# ecd5_target_db register map
Vendor: Texas Instruments
Address unit: 16 bits
Registers are 32-bit, access per field, reset 0x0 unless marked. A register's access mark holds for its fields unless they carry their own. Offsets are as the file gives them; [hi:lo] are bit positions; {n}, {i} and the like mark numbered series; 'fields as' and 'values as' point back to an identical list; <NAME> marks a mode.

## DSS (part 5 of 5) — ipxact12_to_ccs_generated
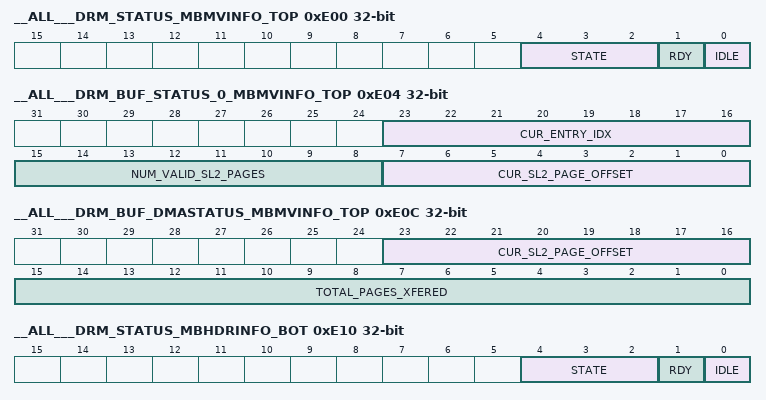
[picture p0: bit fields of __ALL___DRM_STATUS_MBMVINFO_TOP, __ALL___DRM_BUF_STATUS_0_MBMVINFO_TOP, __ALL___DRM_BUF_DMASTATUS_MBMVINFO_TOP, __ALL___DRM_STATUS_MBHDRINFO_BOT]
0xE00 __ALL___DRM_STATUS_MBMVINFO_TOP ro — Status of DRM channel controller forcurrent top MBMVInfo buffer
  [4:2] STATE — Indicates state of the channel control DRM FSM
  [1] RDY — Indicates availability of at least one valid page in SL2 for processing by the ECD core
  [0] IDLE — If "1", indicates that the DRM channel control FSM is IDLE. Used to check for completion of DMA after a terminate request.
0xE04 __ALL___DRM_BUF_STATUS_0_MBMVINFO_TOP ro — Buffer Status for current top MBMVInfo buffer Valid only in frame decoupled mode. Reflects the current internal and DMA status of the buffer
  [23:16] CUR_ENTRY_IDX — Unused
  [15:8] NUM_VALID_SL2_PAGES — Indicates the number of pages currently valid in SL2. This field indicates the number of pages in SL2 available for the ECD core to write into. This count is initialized to the total number of pages (ECD5_BE_BUFFER_CONTROL.DRM_BUF_CFG_[BUFFER_NAME].NUM_PAGES) on DRM initialization. The count is decremented every time ECD writes one page to SL2. The count is incremented whenever the DMA of one page from SL2 to DDR is completed.
  [7:0] CUR_SL2_PAGE_OFFSET — Indicates the SL2 page number where the next data will be written to by the ECD core (MBP); valid values are 0 to DRM_BUF_PARAMS_[BUFFER_NAME].NUM_PAGES - 1; reset on DMA initialization
0xE08 __ALL___DRM_BUF_STATUS_1_MBMVINFO_TOP ro — Buffer Status for current top MBMVInfo buffer Valid only in frame decoupled mode. Reflects the current internal and DMA status of the buffer
  [21:0] CUR_SL2_ADDR — Indicates the SL2 address of the page where the next data will be written to by the ECD core (MBP) ; reset on DMA initialization to SL2 base address of the buffer in SL2
0xE0C __ALL___DRM_BUF_DMASTATUS_MBMVINFO_TOP ro — Buffer DMA Status for current top MBMVInfo buffer Valid only in frame decoupled mode. Reflects the current DMA status of bin stream 3 buffer
  [23:16] CUR_SL2_PAGE_OFFSET — Indicates the SL2 page number from which the next page DMA will happen (read from) when enabling conditions for DMA are met (SL2 page is filled by ECD5 core); valid values are 0 to DRM_BUF_PARAMS_[BUFFER_NAME].NUM_PAGES - 1; reset on DMA initialization
  [15:0] TOTAL_PAGES_XFERED — Indicates the total number of pages for which DMA has completed; reset on DMA initialization
0xE10 __ALL___DRM_STATUS_MBHDRINFO_BOT ro — Status of DRM channel controller forcurrent bottom MBHdrInfo buffer
  fields as __ALL___DRM_STATUS_MBMVINFO_TOP
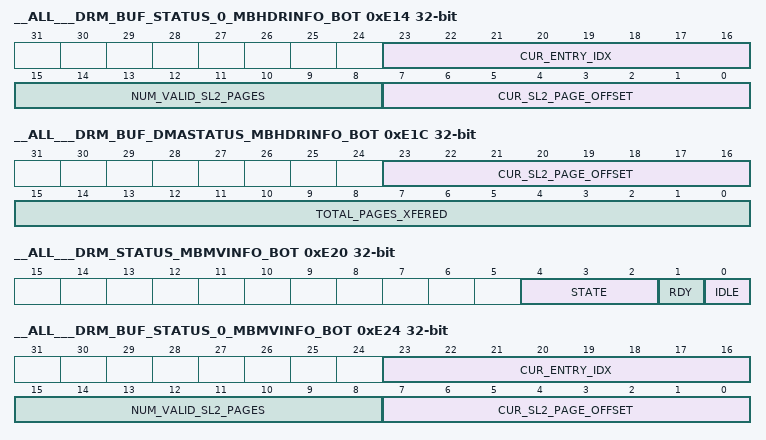
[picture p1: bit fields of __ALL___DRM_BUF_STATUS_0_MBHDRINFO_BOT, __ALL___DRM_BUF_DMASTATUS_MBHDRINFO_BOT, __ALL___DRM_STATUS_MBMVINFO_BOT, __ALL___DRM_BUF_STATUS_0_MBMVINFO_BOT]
0xE14 __ALL___DRM_BUF_STATUS_0_MBHDRINFO_BOT ro — Buffer Status for current bottom MBHdrInfo buffer Valid only in frame decoupled mode. Reflects the current internal and DMA status of the buffer
  [23:16] CUR_ENTRY_IDX — For debug only. Indicates the index of the entry that is currently being written or will be written next by the ECD5 core in the current page; reset on DMA initialization
  [15:8] NUM_VALID_SL2_PAGES — Indicates the number of pages currently valid in SL2. This field indicates the number of pages in SL2 available for the ECD core to write into. This count is initialized to the total number of pages (ECD5_BE_BUFFER_CONTROL.DRM_BUF_CFG_[BUFFER_NAME].NUM_PAGES) on DRM initialization. The count is decremented every time ECD writes one page to SL2. The count is incremented whenever the DMA of one page from SL2 to DDR is completed.
  [7:0] CUR_SL2_PAGE_OFFSET — Indicates the SL2 page number where the next data will be written to by the ECD core (MBP); valid values are 0 to DRM_BUF_PARAMS_[BUFFER_NAME].NUM_PAGES - 1; reset on DMA initialization
0xE18 __ALL___DRM_BUF_STATUS_1_MBHDRINFO_BOT ro — Buffer Status for current bottom MBHdrInfo buffer Valid only in frame decoupled mode. Reflects the current internal and DMA status of the buffer
  fields as __ALL___DRM_BUF_STATUS_1_MBMVINFO_TOP
0xE1C __ALL___DRM_BUF_DMASTATUS_MBHDRINFO_BOT ro — Buffer DMA Status for current bottom MBHdrInfo buffer Valid only in frame decoupled mode. Reflects the current DMA status of bin stream 3 buffer
  fields as __ALL___DRM_BUF_DMASTATUS_MBMVINFO_TOP
0xE20 __ALL___DRM_STATUS_MBMVINFO_BOT ro — Status of DRM channel controller forcurrent bottom MBMVInfo buffer
  fields as __ALL___DRM_STATUS_MBMVINFO_TOP
0xE24 __ALL___DRM_BUF_STATUS_0_MBMVINFO_BOT ro — Buffer Status for current bottom MBMVInfo buffer Valid only in frame decoupled mode. Reflects the current internal and DMA status of the buffer
  fields as __ALL___DRM_BUF_STATUS_0_MBMVINFO_TOP
0xE28 __ALL___DRM_BUF_STATUS_1_MBMVINFO_BOT ro — Buffer Status for current bottom MBMVInfo buffer Valid only in frame decoupled mode. Reflects the current internal and DMA status of the buffer
  fields as __ALL___DRM_BUF_STATUS_1_MBMVINFO_TOP
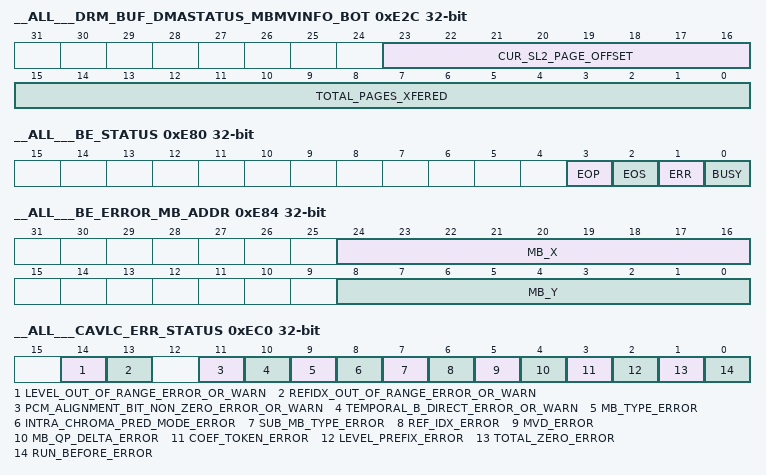
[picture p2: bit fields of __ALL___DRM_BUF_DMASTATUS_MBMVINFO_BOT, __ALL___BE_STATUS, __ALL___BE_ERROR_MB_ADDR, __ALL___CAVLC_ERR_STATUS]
0xE2C __ALL___DRM_BUF_DMASTATUS_MBMVINFO_BOT ro — Buffer DMA Status for current bottom MBMVInfo buffer Valid only in frame decoupled mode. Reflects the current DMA status of bin stream 3 buffer
  fields as __ALL___DRM_BUF_DMASTATUS_MBMVINFO_TOP
0xE80 __ALL___BE_STATUS ro — BE Status
  [3] EOP — Indicates End of Pipe (frame/sub-frame) was detected during decode of the last Macroblock. If set to 1, indicates that the last macroblock is at the end of the frame/sub-frame. On detecting EOP, ECD5 issues EOP interrupt (if enabled) and sets this flag. EOP flag is automatically cleared by ECD5 core if one of the following condition is true: - EN bit in SYSTEM_MMR.ECD5_BE_ENABLE register is set to 1 - hwa_init request is received
  [2] EOS — Indicates End of Slice was detected during decode of the last Macroblock. If set to 1, indicates that the last macroblock is at the end of the slice. When receiving EOS signal from codec engine, ECD5 issues EOS interrupt (if enabled) and sets this flag. EOS flag is automatically cleared if either one of the following condition is true: - EN bit in SYSTEM_MMR.ECD5_BE_UNIT_ENABLE register is set to 1. - EN bit in SYSTEM_MMR.ECD5_BE_ENABLE register is set to 1 - hwa_init request is received
  [1] ERR — Indicates Error was detected during decode of last Macroblock. If set to 1, indicates that the last macroblock had error. When receiving ERR signal from codec engine, ECD5 issues ERR interrupt (if enabled) and sets this flag. ERR flag is automatically cleared if either one of the following condition is true: - EN bit in SYSTEM_MMR.ECD5_BE_UNIT_ENABLE register is set to 1. - EN bit in SYSTEM_MMR.ECD5_BE_ENABLE register is set to 1. - start of new macroblock processing - hwa_init request is received
  [0] BUSY — Indicates whether the BE-MBP is busy 0 - Idle 1 - Busy
0xE84 __ALL___BE_ERROR_MB_ADDR ro — Error MB address This register provides the address of the MB in which error was detected by BE core or by CAVLC
  [24:16] MB_X — Specifies the X position of the error MB
  [8:0] MB_Y — Specifies the Y position of the error MB
0xEA0 __ALL___BE_CORE_STATIC_MB_COUNT rw — Static MB count
  [31:0] BE_CORE_STATIC_MB_COUNT — Count of H.241 static MBs (section 8.3.2.8 of H.241 standard)
0xEA4 __ALL___BE_CORE_ERR_STATUS — BE Error Status
  [0] TEMPORAL_B_DIRECT_MISSING_REF_ERROR rw — This bit is set if (frame_id, bottomFieldFlag) is not found in RefPicList.
0xEC0 __ALL___CAVLC_ERR_STATUS — CAVLC Error Status
  [14] LEVEL_OUT_OF_RANGE_ERROR_OR_WARN rw — This bit is set if level becomes out of range [-2^(7+bitDepth), 2^(7+bitDepth)-1] (due to error in level_suffix).
  [13] REFIDX_OUT_OF_RANGE_ERROR_OR_WARN rw — This bit is set if ref_idx_lx ( x == 0 or 1 ) out of the range [0,ECD5_BE_FUNC.CAVLC_REF_IDX_MAX_LX.VALUE] is detected
  [11] PCM_ALIGNMENT_BIT_NON_ZERO_ERROR_OR_WARN rw — This bit is set if pcm_alignment_zero_bit that is not "0" is detected
  [10] TEMPORAL_B_DIRECT_ERROR_OR_WARN rw — This bit is set if Temporal B Direct MB is detected.
  [9] MB_TYPE_ERROR rw — This bit is set if decoded mb_type_id is out of range. The range of mb_type_id is mb_type < 26 in I_SLICE, mb_type < 31 in P_SLICE, mb_type < 49 in B_SLICE
  [8] INTRA_CHROMA_PRED_MODE_ERROR rw — This bit is set if decoded intra_chroma_pred_mode is out of range. The range of intra_chroma_pred_mode is: intra_chroma_pred_mode < 4
  [7] SUB_MB_TYPE_ERROR rw — This bit is set if decoded sub_mb_type is out of range The range of sub_mb_type is: sub_mb_type_id < 4 in P_SLICE, sub_mb_type_id < 13 in B_SLICE.
  [6] REF_IDX_ERROR rw — This bit is set if decoded ref_idx_l0 or ref_idx_l1 is greater than 31.
  [5] MVD_ERROR rw — This bit is set if decoded MVD is out of range. The range of MVD is different between horizontal and vertical (Horizontal and vertical MVD have different out of range detectors) Valid Horizontal MVD range is [-16383,16383] in quarter-pel. Valid Vertical MVD range is [-4095,4095] in quarter-pel.
  [4] MB_QP_DELTA_ERROR rw — This bit is set if decoded mb_qp_delta is out of range. The range of mb_qp_delta is defined as follows: [-26,25] when bitDepth == 8, [-20,31] when bitDepth == 10, [-14,37] when bitDepth == 12.
  [3] COEF_TOKEN_ERROR rw — This bit is set if coef_token in bitstream is out of table or numcoef > max_coeff_num. * Caution: 8<=nC table is 6bit fixed length, but has error in the case 0b000010 and 0b000111. * Max_coeff_num is the number of maximum coefficients derived from block size, 15 or 16. * numcoef is the value derived from coef_token table.
  [2] LEVEL_PREFIX_ERROR rw — This bit is set if decoded level_prefix is out of range. The range of level_prefix is [0, (11+bitDepth)].
  [1] TOTAL_ZERO_ERROR rw — This bit is set if total zeros in bitstream is out of table or num_coeff + total_zeros > max_coeff_num.
  [0] RUN_BEFORE_ERROR rw — This bit is set if run_before in bitstream is out of table.
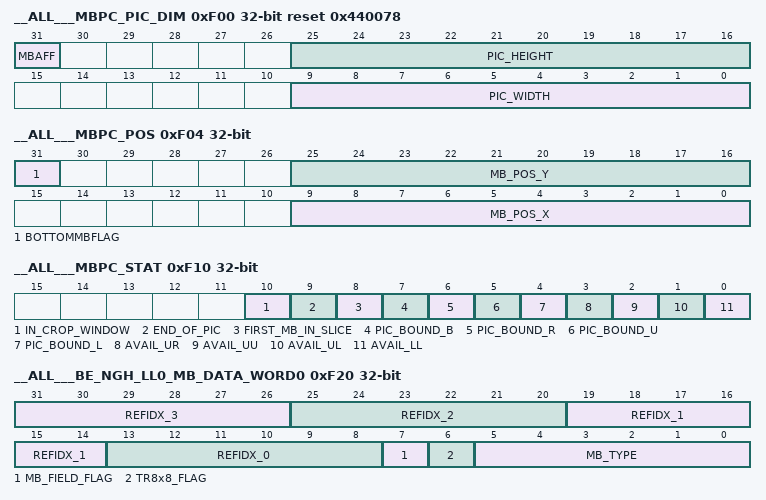
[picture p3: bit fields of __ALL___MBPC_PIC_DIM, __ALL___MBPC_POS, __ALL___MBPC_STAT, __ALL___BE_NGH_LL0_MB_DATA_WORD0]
0xF00 __ALL___MBPC_PIC_DIM rw reset 0x440078 — BE MBPC Picture Dimensions
  [31] MBAFF — If "1", current picture is MBAFF
  [25:16] PIC_HEIGHT — PictureHeight in MBs
  [9:0] PIC_WIDTH — Picture Width in MBs
0xF04 __ALL___MBPC_POS rw — BE MBPC Position
  [31] BOTTOMMBFLAG
  [25:16] MB_POS_Y — MB Position in X direction
  [9:0] MB_POS_X — MB Position in X direction
0xF08 __ALL___MBPC_PMC ro — BE MBPC MB count in picture
  [27:0] PIC_MB_COUNT — Picture level MB Count
0xF0C __ALL___MBPC_SMC ro — BE MBPC MB count in slice
  [27:0] SLICE_MB_COUNT — Slice level MB Count
0xF10 __ALL___MBPC_STAT — BE MBPC Status
  [10] IN_CROP_WINDOW rw — In crop window flag(for SVC)
  [9] END_OF_PIC rw — End of picture flag
  [8] FIRST_MB_IN_SLICE rw — First mb in slice flag
  [7] PIC_BOUND_B rw — Picture boundary bottom
  [6] PIC_BOUND_R rw — Picture boundary right
  [5] PIC_BOUND_U rw — Picture boundary top
  [4] PIC_BOUND_L rw — Picture boundary left
  [3] AVAIL_UR rw — UR neigbhor available
  [2] AVAIL_UU rw — UU neigbhor available
  [1] AVAIL_UL rw — UL neigbhor available
  [0] AVAIL_LL rw — LL neigbhor available
0xF20 __ALL___BE_NGH_LL0_MB_DATA_WORD0 rw — BE Left -Even Neighboring MB Data Word0
  [31:26] REFIDX_3 — L1 Reference Index for block # 13
  [25:20] REFIDX_2 — L1 Reference Index for block # 5
  [19:14] REFIDX_1 — L0 Reference Index for block # 13
  [13:8] REFIDX_0 — L0 Reference Index for block # 5
  [7] MB_FIELD_FLAG — MB Field Flag. Valid only for MBAFF
  [6] TR8x8_FLAG — Transform 8x8 Mode flag
  [5:0] MB_TYPE
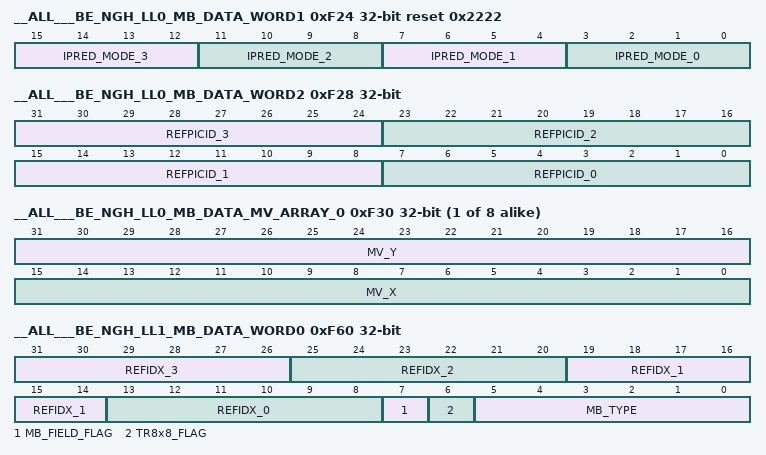
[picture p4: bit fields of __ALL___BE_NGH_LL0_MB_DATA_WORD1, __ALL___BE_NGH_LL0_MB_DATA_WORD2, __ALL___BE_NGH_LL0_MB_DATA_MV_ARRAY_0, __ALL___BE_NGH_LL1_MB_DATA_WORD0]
0xF24 __ALL___BE_NGH_LL0_MB_DATA_WORD1 reset 0x2222 — BE Left -Even Neighboring MB Data Word1
  [15:12] IPRED_MODE_3 rw — ipred_mode for block #15
  [11:8] IPRED_MODE_2 rw — ipred_mode for block #13
  [7:4] IPRED_MODE_1 rw — ipred_mode for block #7
  [3:0] IPRED_MODE_0 rw — ipred_mode for block #5
0xF28 __ALL___BE_NGH_LL0_MB_DATA_WORD2 rw — BE Left -Even Neighboring MB Data Word2
  [31:24] REFPICID_3 — L1 Reference PicId for block # 13
  [23:16] REFPICID_2 — L1 Reference PicId for block # 5
  [15:8] REFPICID_1 — L0 Reference PicId for block # 13
  [7:0] REFPICID_0 — L0 Reference PicId for block # 5
{0xF30+4i} __ALL___BE_NGH_LL0_MB_DATA_MV_ARRAY_{i} rw (i=0..7) — BE Left -Even Neighboring MB Data MV Register Array Indexed from 0 to 7
  [31:16] MV_Y — Ln Motion Vector, Y position for block M where index n M 0 0 10 1 0 11 2 0 14 3 0 15 4 1 10 5 1 11 6 1 14 7 1 15
  [15:0] MV_X — Ln Motion Vector, X position for block M where index n M 0 0 10 1 0 11 2 0 14 3 0 15 4 1 10 5 1 11 6 1 14 7 1 15
0xF60 __ALL___BE_NGH_LL1_MB_DATA_WORD0 rw — BE Left -Odd Neighboring MB Data Word0
  fields as __ALL___BE_NGH_LL0_MB_DATA_WORD0
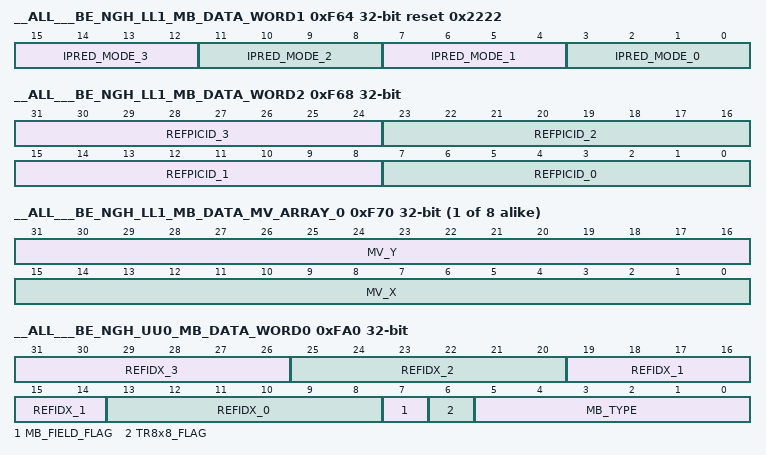
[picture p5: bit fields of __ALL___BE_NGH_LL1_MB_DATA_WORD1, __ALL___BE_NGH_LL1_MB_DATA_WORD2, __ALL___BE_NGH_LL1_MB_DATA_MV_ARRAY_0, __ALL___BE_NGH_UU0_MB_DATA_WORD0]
0xF64 __ALL___BE_NGH_LL1_MB_DATA_WORD1 reset 0x2222 — BE Left -Odd Neighboring MB Data Word1
  fields as __ALL___BE_NGH_LL0_MB_DATA_WORD1
0xF68 __ALL___BE_NGH_LL1_MB_DATA_WORD2 rw — BE Left -Odd Neighboring MB Data Word2
  fields as __ALL___BE_NGH_LL0_MB_DATA_WORD2
{0xF70+4i} __ALL___BE_NGH_LL1_MB_DATA_MV_ARRAY_{i} rw (i=0..7) — BE Left -Odd Neighboring MB Data MV Register Array Indexed from 0 to 7
  fields as __ALL___BE_NGH_LL0_MB_DATA_MV_ARRAY_0
0xFA0 __ALL___BE_NGH_UU0_MB_DATA_WORD0 rw — BE Upper -Even Neighboring MB Data Word0
  [31:26] REFIDX_3 — L1 Reference Index for block # 14
  [25:20] REFIDX_2 — L1 Reference Index for block # 10
  [19:14] REFIDX_1 — L0 Reference Index for block # 14
  [13:8] REFIDX_0 — L0 Reference Index for block # 10
  [7] MB_FIELD_FLAG — MB Field Flag. Valid only for MBAFF
  [6] TR8x8_FLAG — Transform 8x8 Mode flag
  [5:0] MB_TYPE
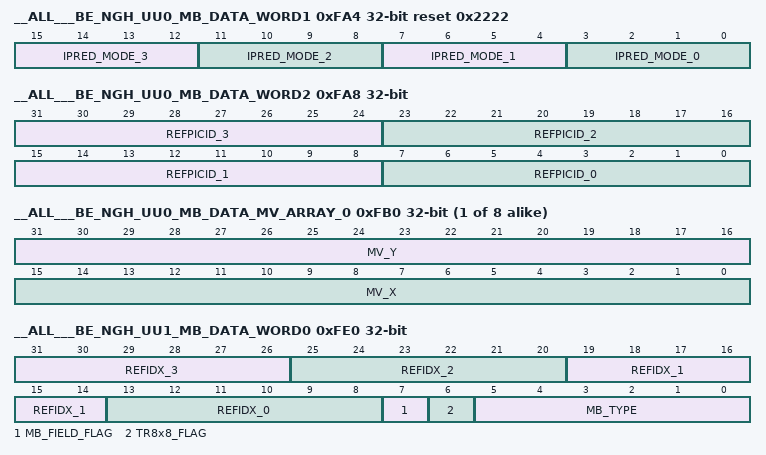
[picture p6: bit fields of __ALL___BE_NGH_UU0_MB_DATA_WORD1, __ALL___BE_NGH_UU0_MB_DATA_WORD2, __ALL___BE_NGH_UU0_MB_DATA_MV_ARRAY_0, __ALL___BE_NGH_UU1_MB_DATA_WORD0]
0xFA4 __ALL___BE_NGH_UU0_MB_DATA_WORD1 reset 0x2222 — BE Upper -Even Neighboring MB Data Word1
  [15:12] IPRED_MODE_3 rw — ipred_mode for block #15
  [11:8] IPRED_MODE_2 rw — ipred_mode for block #14
  [7:4] IPRED_MODE_1 rw — ipred_mode for block #11
  [3:0] IPRED_MODE_0 rw — ipred_mode for block #10
0xFA8 __ALL___BE_NGH_UU0_MB_DATA_WORD2 rw — BE Upper -Even Neighboring MB Data Word2
  [31:24] REFPICID_3 — L1 Reference PicId for block # 14
  [23:16] REFPICID_2 — L1 Reference PicId for block # 10
  [15:8] REFPICID_1 — L0 Reference PicId for block # 14
  [7:0] REFPICID_0 — L0 Reference PicId for block # 10
{0xFB0+4i} __ALL___BE_NGH_UU0_MB_DATA_MV_ARRAY_{i} rw (i=0..7) — BE Upper -Even Neighboring MB Data MV Register Array Indexed from 0 to 7
  fields as __ALL___BE_NGH_LL0_MB_DATA_MV_ARRAY_0
0xFE0 __ALL___BE_NGH_UU1_MB_DATA_WORD0 rw — BE Upper -Odd Neighboring MB Data MV0
  fields as __ALL___BE_NGH_UU0_MB_DATA_WORD0
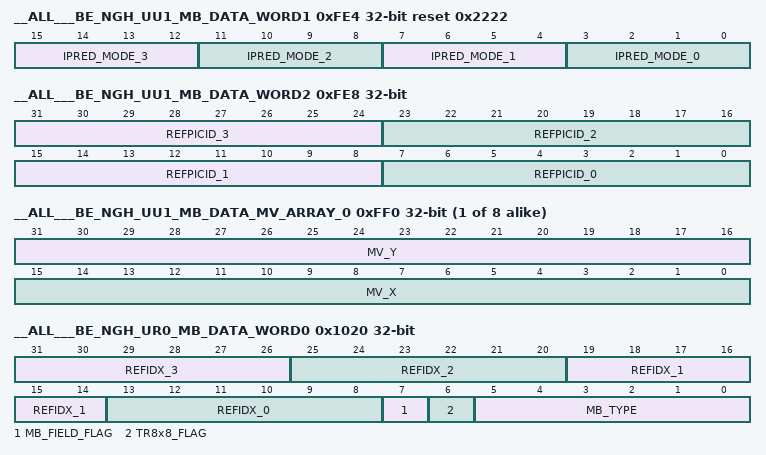
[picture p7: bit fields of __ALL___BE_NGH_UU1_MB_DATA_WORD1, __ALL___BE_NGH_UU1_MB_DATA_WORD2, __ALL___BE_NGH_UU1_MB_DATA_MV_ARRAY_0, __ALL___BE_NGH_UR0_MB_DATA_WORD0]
0xFE4 __ALL___BE_NGH_UU1_MB_DATA_WORD1 reset 0x2222 — BE Upper -Odd Neighboring MB Data Word1
  fields as __ALL___BE_NGH_UU0_MB_DATA_WORD1
0xFE8 __ALL___BE_NGH_UU1_MB_DATA_WORD2 rw — BE Upper -Odd Neighboring MB Data Word2
  fields as __ALL___BE_NGH_UU0_MB_DATA_WORD2
{0xFF0+4i} __ALL___BE_NGH_UU1_MB_DATA_MV_ARRAY_{i} rw (i=0..7) — BE Upper -Odd Neighboring MB Data MV Register Array Indexed from 0 to 7
  fields as __ALL___BE_NGH_LL0_MB_DATA_MV_ARRAY_0
0x1020 __ALL___BE_NGH_UR0_MB_DATA_WORD0 rw — BE Upper Right -Even Neighboring MB Data Word0
  fields as __ALL___BE_NGH_UU0_MB_DATA_WORD0
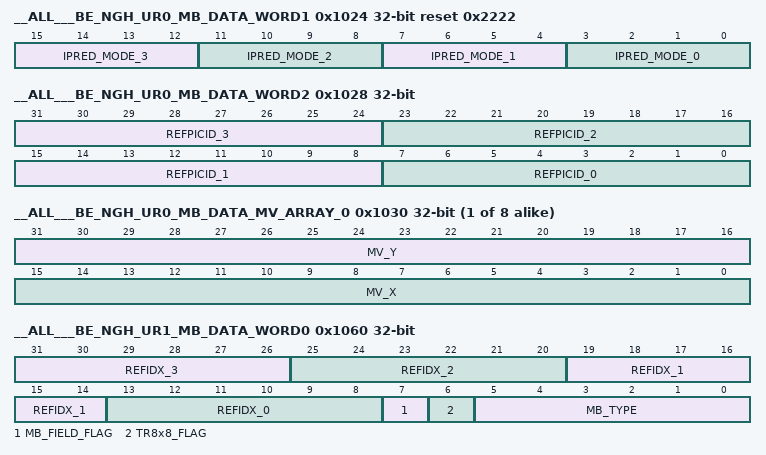
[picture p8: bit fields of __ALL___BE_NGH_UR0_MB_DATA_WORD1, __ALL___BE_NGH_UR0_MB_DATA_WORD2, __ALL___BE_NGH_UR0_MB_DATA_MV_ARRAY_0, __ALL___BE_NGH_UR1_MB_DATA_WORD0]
0x1024 __ALL___BE_NGH_UR0_MB_DATA_WORD1 reset 0x2222 — BE Upper Right -Even Neighboring MB Data Word1
  fields as __ALL___BE_NGH_UU0_MB_DATA_WORD1
0x1028 __ALL___BE_NGH_UR0_MB_DATA_WORD2 rw — BE Upper Right -Even Neighboring MB Data Word2
  fields as __ALL___BE_NGH_UU0_MB_DATA_WORD2
{0x1030+4i} __ALL___BE_NGH_UR0_MB_DATA_MV_ARRAY_{i} rw (i=0..7) — BE Upper Right -Even Neighboring MB Data MV Register Array Indexed from 0 to 7
  fields as __ALL___BE_NGH_LL0_MB_DATA_MV_ARRAY_0
0x1060 __ALL___BE_NGH_UR1_MB_DATA_WORD0 rw — BE Upper Right -Odd Neighboring MB Data Word0
  fields as __ALL___BE_NGH_UU0_MB_DATA_WORD0
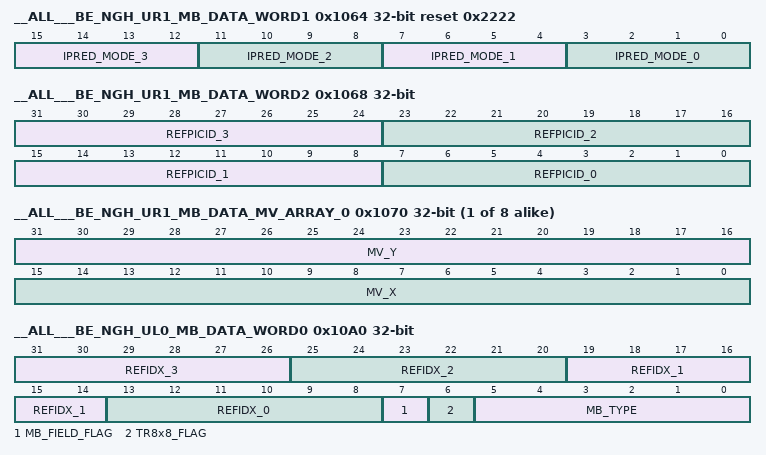
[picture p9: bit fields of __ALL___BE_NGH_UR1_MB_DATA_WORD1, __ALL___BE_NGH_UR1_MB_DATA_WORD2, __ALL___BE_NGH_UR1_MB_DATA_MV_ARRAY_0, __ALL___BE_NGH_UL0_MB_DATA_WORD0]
0x1064 __ALL___BE_NGH_UR1_MB_DATA_WORD1 reset 0x2222 — BE Upper Right -Odd Neighboring MB Data Word1
  fields as __ALL___BE_NGH_UU0_MB_DATA_WORD1
0x1068 __ALL___BE_NGH_UR1_MB_DATA_WORD2 rw — BE Upper Right -Odd Neighboring MB Data Word2
  fields as __ALL___BE_NGH_UU0_MB_DATA_WORD2
{0x1070+4i} __ALL___BE_NGH_UR1_MB_DATA_MV_ARRAY_{i} rw (i=0..7) — BE Upper Right -Odd Neighboring MB Data MV Register Array Indexed from 0 to 7
  fields as __ALL___BE_NGH_LL0_MB_DATA_MV_ARRAY_0
0x10A0 __ALL___BE_NGH_UL0_MB_DATA_WORD0 rw — BE Upper Left -Even Neighboring MB Data Word0
  fields as __ALL___BE_NGH_UU0_MB_DATA_WORD0
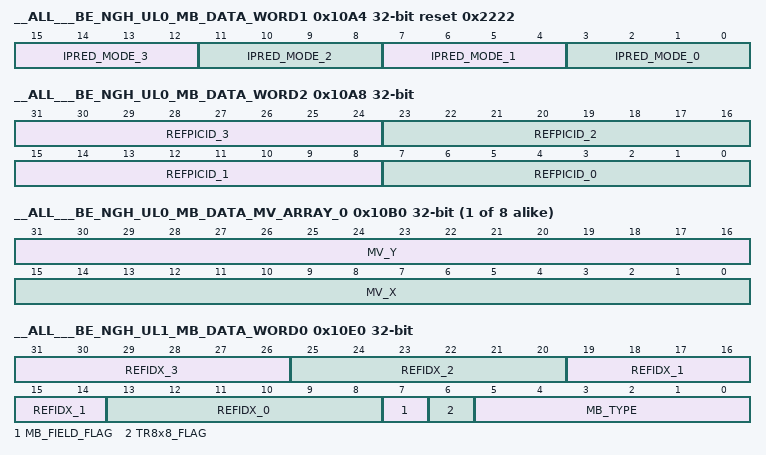
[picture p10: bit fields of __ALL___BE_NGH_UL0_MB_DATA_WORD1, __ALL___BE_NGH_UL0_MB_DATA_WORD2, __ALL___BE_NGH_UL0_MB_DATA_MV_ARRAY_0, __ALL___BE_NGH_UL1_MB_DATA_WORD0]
0x10A4 __ALL___BE_NGH_UL0_MB_DATA_WORD1 reset 0x2222 — BE Upper Left -Even Neighboring MB Data Word1
  fields as __ALL___BE_NGH_UU0_MB_DATA_WORD1
0x10A8 __ALL___BE_NGH_UL0_MB_DATA_WORD2 rw — BE Upper Left -Even Neighboring MB Data Word2
  fields as __ALL___BE_NGH_UU0_MB_DATA_WORD2
{0x10B0+4i} __ALL___BE_NGH_UL0_MB_DATA_MV_ARRAY_{i} rw (i=0..7) — BE Upper Left -Even Neighboring MB Data MV Register Array Indexed from 0 to 7
  fields as __ALL___BE_NGH_LL0_MB_DATA_MV_ARRAY_0
0x10E0 __ALL___BE_NGH_UL1_MB_DATA_WORD0 rw — BE Upper Left -Odd Neighboring MB Data Word0
  fields as __ALL___BE_NGH_UU0_MB_DATA_WORD0
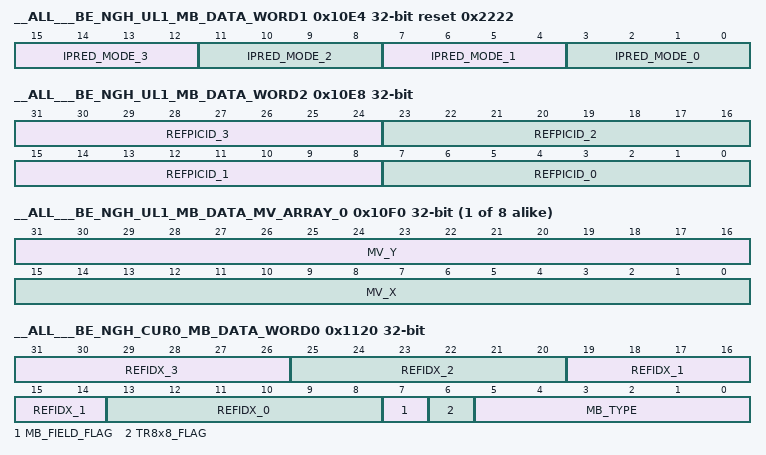
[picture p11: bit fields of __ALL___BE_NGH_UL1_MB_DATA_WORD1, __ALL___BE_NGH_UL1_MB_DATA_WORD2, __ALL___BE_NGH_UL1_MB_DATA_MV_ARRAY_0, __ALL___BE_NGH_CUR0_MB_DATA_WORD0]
0x10E4 __ALL___BE_NGH_UL1_MB_DATA_WORD1 reset 0x2222 — BE Upper Left -Odd Neighboring MB Data Word1
  fields as __ALL___BE_NGH_UU0_MB_DATA_WORD1
0x10E8 __ALL___BE_NGH_UL1_MB_DATA_WORD2 rw — BE Upper Left -Odd Neighboring MB Data Word2
  fields as __ALL___BE_NGH_UU0_MB_DATA_WORD2
{0x10F0+4i} __ALL___BE_NGH_UL1_MB_DATA_MV_ARRAY_{i} rw (i=0..7) — BE Upper Left -Odd Neighboring MB Data MV Register Array Indexed from 0 to 7
  fields as __ALL___BE_NGH_LL0_MB_DATA_MV_ARRAY_0
0x1120 __ALL___BE_NGH_CUR0_MB_DATA_WORD0 rw — BE Current -Even Neighboring MB Data Word0 (Needed Only for Bottom MB in MBAFF mode)
  fields as __ALL___BE_NGH_UU0_MB_DATA_WORD0
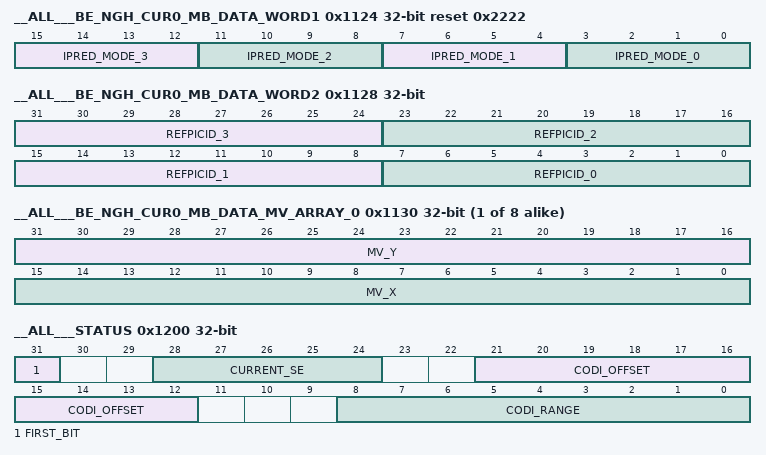
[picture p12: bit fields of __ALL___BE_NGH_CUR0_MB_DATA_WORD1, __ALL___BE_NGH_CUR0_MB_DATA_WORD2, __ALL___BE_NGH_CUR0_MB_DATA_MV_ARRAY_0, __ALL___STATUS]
0x1124 __ALL___BE_NGH_CUR0_MB_DATA_WORD1 reset 0x2222 — BE Current -Even Neighboring MB Data Word1
  fields as __ALL___BE_NGH_UU0_MB_DATA_WORD1
0x1128 __ALL___BE_NGH_CUR0_MB_DATA_WORD2 rw — BE Current -Even Neighboring MB Data Word2
  fields as __ALL___BE_NGH_UU0_MB_DATA_WORD2
{0x1130+4i} __ALL___BE_NGH_CUR0_MB_DATA_MV_ARRAY_{i} rw (i=0..7) — BE Current -Even Neighboring MB Data MV Register Array Indexed from 0 to 7
  fields as __ALL___BE_NGH_LL0_MB_DATA_MV_ARRAY_0
0x1200 __ALL___STATUS — Current status of CABAC Engine
  [31] FIRST_BIT rw — This bit equal to 1 indicates that the next bit put by CABAC is the first bit since the last CABAC initialization. This register is automatically set by CABAC encoder. This flag is ignored in decoding
  [28:24] CURRENT_SE ro — Current Syntax Element
  [21:12] CODI_OFFSET rw — Current Code Offset for CABAC encoding/decoding
  [8:0] CODI_RANGE rw — Current Code Range for CABAC encoding/decoding
0x1204 __ALL___BITS_OSTD rw — CABAC Outstanding bits
  [31:0] BITS_OSTD — Total number of outstanding bits in CABAC encoder. This register is not used in decoding.This register is maintained by ECD5.The value of this register is undefined if an error interrupt (INT_ERRx) is issued
0x1208 __ALL___BIN_COUNT rw — CABAC Bin count
  [31:0] COUNT — Total number of bins encoded/decoded. This register is reset to zero when H.264 core is invoked for a first macroblock in a slice or when CABAC decoder is invoked for an MB level execution. The value of this register is undefined if an error interrupt (int_err) is issued
{0x1300+4i} __ALL___NGH_UU0_PING_ARRAY_{i} rw (i=0..5) — Neighbouring A Top ping buffer
  [31:0] DATA
{0x1320+4i} __ALL___NGH_UU0_PONG_ARRAY_{i} rw (i=0..5) — Neighbouring A Top pong buffer
  [31:0] DATA
{0x1340+4i} __ALL___NGH_UU1_PING_ARRAY_{i} rw (i=0..5) — Neighbouring A Bottom ping buffer
  [31:0] DATA
{0x1360+4i} __ALL___NGH_UU1_PONG_ARRAY_{i} rw (i=0..5) — Neighbouring A Bottom pong buffer
  [31:0] DATA
{0x1380+4i} __ALL___NGH_LL0_PING_ARRAY_{i} rw (i=0..5) — Neighbouring B Top ping buffer
  [31:0] DATA
{0x13A0+4i} __ALL___NGH_LL0_PONG_ARRAY_{i} rw (i=0..5) — Neighbouring B Top pong buffer
  [31:0] DATA
{0x13C0+4i} __ALL___NGH_LL1_PING_ARRAY_{i} rw (i=0..5) — Neighbouring B Bottom ping buffer
  [31:0] DATA
{0x13E0+4i} __ALL___NGH_LL1_PONG_ARRAY_{i} rw (i=0..5) — Neighbouring B Bottom pong buffer
  [31:0] DATA
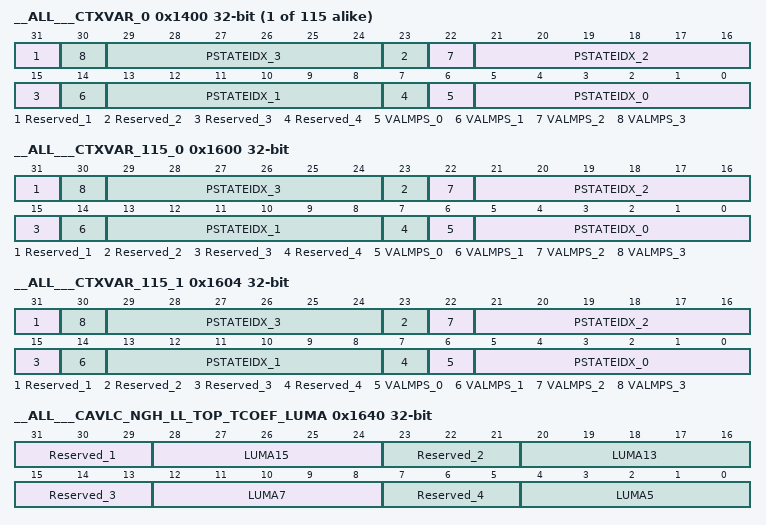
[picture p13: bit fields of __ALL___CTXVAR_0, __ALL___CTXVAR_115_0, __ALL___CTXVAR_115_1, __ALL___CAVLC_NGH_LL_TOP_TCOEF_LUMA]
{0x1400+4i} __ALL___CTXVAR_{i} (i=0..114) — CABAC Context Variable Register
  [39-8n] Reserved_{n} ro (n=1..4) — Fixed to 0. Writing this field is ignored. Reading this field returns always 0.
  [8n+6] VALMPS_{n} rw (n=0..3) — Most probable symbol for this CABAC context index
  [8n+5:8n] PSTATEIDX_{n} rw (n=0..3) — Probablility state index for this CABAC context index
0x1600 __ALL___CTXVAR_115_0 — CABAC Context Variable Register for contexts starting at 1024
  fields as __ALL___CTXVAR_0
0x1604 __ALL___CTXVAR_115_1 — CABAC Context Variable Register for contexts starting at 1024
  fields as __ALL___CTXVAR_0
0x1640 __ALL___CAVLC_NGH_LL_TOP_TCOEF_LUMA — CAVLC Neighbouring Total Coefficient Data for Luma blocks in Top MB of Left Neighbouring MB pair
  [39-8n:37-8n] Reserved_{n} ro (n=1..4) — Fixed to 0. Writing this field is ignored. Reading this field returns always 0.
  [28:24] LUMA15 rw — This register shows total_coef_luma15 of left_top data buffer. Writing this register causes the update of total_coef_luma15 field of left_top data buffer. Range of total_coef_luma is [0:16].
  [20:16] LUMA13 rw — This register shows total_coef_luma13 of left_top data buffer. Writing this register causes the update of total_coef_luma13 field of left_top data buffer. Range of total_coef_luma is [0:16].
  [12:8] LUMA7 rw — This register shows total_coef_luma7 of left_top data buffer. Writing this register causes the update of total_coef_luma7 field of left_top data buffer. Range of total_coef_luma is [0:16].
  [4:0] LUMA5 rw — This register shows total_coef_luma5 of left_top data buffer. Writing this register causes the update of total_coef_luma5 field of left_top data buffer. Range of total_coef_luma is [0:16].
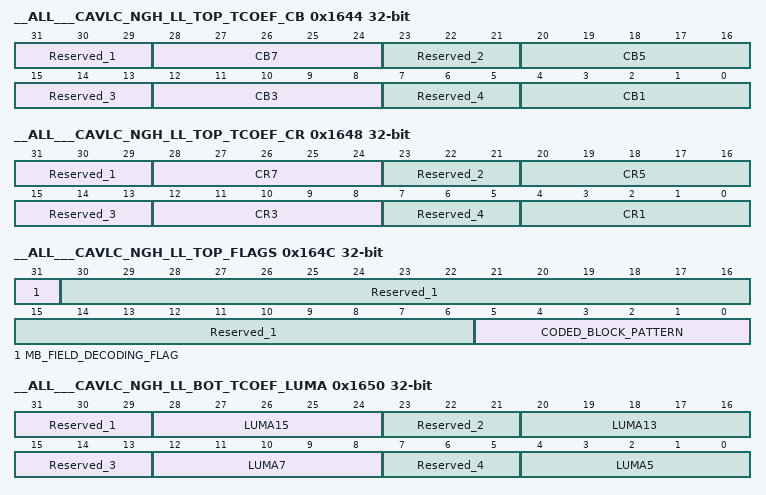
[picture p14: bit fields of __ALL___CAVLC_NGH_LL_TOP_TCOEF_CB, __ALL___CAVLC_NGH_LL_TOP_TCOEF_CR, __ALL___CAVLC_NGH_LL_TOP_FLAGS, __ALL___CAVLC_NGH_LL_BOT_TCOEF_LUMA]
0x1644 __ALL___CAVLC_NGH_LL_TOP_TCOEF_CB — CAVLC Neighbouring Total Coefficient Data for CB blocks in Top MB of Left Neighbouring MB pair
  [39-8n:37-8n] Reserved_{n} ro (n=1..4) — Fixed to 0. Writing this field is ignored. Reading this field returns always 0.
  [28:24] CB7 rw — This register shows total_coef_cb7 of left_top data buffer. Writing this register causes the update of total_coef_cb7 field of left_top data buffer. Range of total_coef_chroma is [0:16]. Only valid for 4:2:2 mode.
  [20:16] CB5 rw — This register shows total_coef_cb5 of left_top data buffer. Writing this register causes the update of total_coef_cb5 field of left_top data buffer. Range of total_coef_chroma is [0:16]. Only valid for 4:2:2 mode.
  [12:8] CB3 rw — This register shows total_coef_cb3 of left_top data buffer. Writing this register causes the update of total_coef_cb3 field of left_top data buffer. Range of total_coef_chroma is [0:16].
  [4:0] CB1 rw — This register shows total_coef_cb1 of left_top data buffer. Writing this register causes the update of total_coef_cb1 field of left_top data buffer. Range of total_coef_chroma is [0:16].
0x1648 __ALL___CAVLC_NGH_LL_TOP_TCOEF_CR — CAVLC Neighbouring Total Coefficient Data for CR blocks in Top MB of Left Neighbouring MB pair
  [39-8n:37-8n] Reserved_{n} ro (n=1..4) — Fixed to 0. Writing this field is ignored. Reading this field returns always 0.
  [28:24] CR7 rw — This register shows total_coef_cr7 of left_top data buffer. Writing this register causes the update of total_coef_cr7 field of left_top data buffer. Range of total_coef_chroma is [0:16]. Only valid for 4:2:2 mode.
  [20:16] CR5 rw — This register shows total_coef_cr5 of left_top data buffer. Writing this register causes the update of total_coef_cr5 field of left_top data buffer. Range of total_coef_chroma is [0:16]. Only valid for 4:2:2 mode.
  [12:8] CR3 rw — This register shows total_coef_cr3 of left_top data buffer. Writing this register causes the update of total_coef_cr3 field of left_top data buffer. Range of total_coef_chroma is [0:16].
  [4:0] CR1 rw — This register shows total_coef_cr1 of left_top data buffer. Writing this register causes the update of total_coef_cr1 field of left_top data buffer. Range of total_coef_chroma is [0:16].
0x164C __ALL___CAVLC_NGH_LL_TOP_FLAGS — CAVLC Neighbouring Flags in Top MB of Left Neighbouring MB pair
  [31] MB_FIELD_DECODING_FLAG rw — This register shows mb_field_decoding_flag of left_top data buffer. Writing this register causes the update of mb_field_decoding_flag field of left_top data buffer.
  [30:6] Reserved_1 ro — Fixed to 0. Writing this field is ignored. Reading this field returns always 0.
  [5:0] CODED_BLOCK_PATTERN rw — This register shows coded_block_pattern of left_top data buffer. Writing this register causes the update of coded_block_pattern field of left_top data buffer.
0x1650 __ALL___CAVLC_NGH_LL_BOT_TCOEF_LUMA — CAVLC Neighbouring Total Coefficient Data for Luma blocks in Bottom MB of Left Neighbouring MB pair
  [39-8n:37-8n] Reserved_{n} ro (n=1..4) — Fixed to 0. Writing this field is ignored. Reading this field returns always 0.
  [28:24] LUMA15 rw — This register shows total_coef_luma15 of left_bottom_data_array. Writing this register causes the update of total_coef_luma15 field of left_bottom_data_array. Range of total_coef_luma is [0:16].
  [20:16] LUMA13 rw — This register shows total_coef_luma13 of left_bottom_data_array. Writing this register causes the update of total_coef_luma13 field of left_bottom_data_array. Range of total_coef_luma is [0:16].
  [12:8] LUMA7 rw — This register shows total_coef_luma7 of left_bottom_data_array. Writing this register causes the update of total_coef_luma7 field of left_bottom_data_array. Range of total_coef_luma is [0:16].
  [4:0] LUMA5 rw — This register shows total_coef_luma5 of left_bottom_data_array. Writing this register causes the update of total_coef_luma5 field of left_bottom_data_array. Range of total_coef_luma is [0:16].
0x1654 __ALL___CAVLC_NGH_LL_BOT_TCOEF_CB — CAVLC Neighbouring Total Coefficient Data for CB blocks in Bottom MB of Left Neighbouring MB pair
  [39-8n:37-8n] Reserved_{n} ro (n=1..4) — Fixed to 0. Writing this field is ignored. Reading this field returns always 0.
  [28:24] CB7 rw — This register shows total_coef_cb7 of left_bottom data buffer. Writing this register causes the update of total_coef_cb7 field of left_bottom data buffer. Range of total_coef_chroma is [0:16]. Only valid for 4:2:2 mode.
  [20:16] CB5 rw — This register shows total_coef_cb5 of left_bottom data buffer. Writing this register causes the update of total_coef_cb5 field of left_bottom data buffer. Range of total_coef_chroma is [0:16]. Only valid for 4:2:2 mode.
  [12:8] CB3 rw — This register shows total_coef_cb3 of left_bottom data buffer. Writing this register causes the update of total_coef_cb3 field of left_bottom data buffer. Range of total_coef_chroma is [0:16].
  [4:0] CB1 rw — This register shows total_coef_cb1 of left_bottom data buffer. Writing this register causes the update of total_coef_cb1 field of left_bottom data buffer. Range of total_coef_chroma is [0:16].
0x1658 __ALL___CAVLC_NGH_LL_BOT_TCOEF_CR — CAVLC Neighbouring Total Coefficient Data for CR blocks in Bottom MB of Left Neighbouring MB pair
  [39-8n:37-8n] Reserved_{n} ro (n=1..4) — Fixed to 0. Writing this field is ignored. Reading this field returns always 0.
  [28:24] CR7 rw — This register shows total_coef_cr7 of left_bottom data buffer. Writing this register causes the update of total_coef_cr7 field of left_bottom data buffer. Range of total_coef_chroma is [0:16]. Only valid for 4:2:2 mode.
  [20:16] CR5 rw — This register shows total_coef_cr5 of left_bottom data buffer. Writing this register causes the update of total_coef_cr5 field of left_bottom data buffer. Range of total_coef_chroma is [0:16]. Only valid for 4:2:2 mode.
  [12:8] CR3 rw — This register shows total_coef_cr3 of left_bottom data buffer. Writing this register causes the update of total_coef_cr3 field of left_bottom data buffer. Range of total_coef_chroma is [0:16].
  [4:0] CR1 rw — This register shows total_coef_cr1 of left_bottom data buffer. Writing this register causes the update of total_coef_cr1 field of left_bottom data buffer. Range of total_coef_chroma is [0:16].
0x165C __ALL___CAVLC_NGH_LL_BOT_FLAGS — CAVLC Neighbouring Flags in Bottom MB of Left Neighbouring MB pair
  [31] MB_FIELD_DECODING_FLAG rw — This register shows mb_field_decoding_flag of left_bottom_data_array. Writing this register causes the update of mb_field_decoding_flag field of left_bottom_data_array.
  [30:6] Reserved_1 ro — Fixed to 0. Writing this field is ignored. Reading this field returns always 0.
  [5:0] CODED_BLOCK_PATTERN rw — This register shows coded_block_pattern of left_bottom_data_array. Writing this register causes the update of coded_block_pattern field of left_bottom_data_array.
0x1660 __ALL___CAVLC_NGH_PREV_TCOEF_LUMA0 — CAVLC Previous Data buffer Total Coefficient Data for Luma
  [39-8n:37-8n] Reserved_{n} ro (n=1..4) — Fixed to 0. Writing this field is ignored. Reading this field returns always 0.
  [28:24] LUMA15 rw — This register shows total_coef_luma15 of prev data buffer. Writing this register causes the update of total_coef_luma15 field of prev data buffer. Range of total_coef_luma is [0:16].
  [20:16] LUMA13 rw — This register shows total_coef_luma13 of prev data buffer. Writing this register causes the update of total_coef_luma13 field of prev data buffer. Range of total_coef_luma is [0:16].
  [12:8] LUMA7 rw — This register shows total_coef_luma7 of prev data buffer. Writing this register causes the update of total_coef_luma7 field of prev data buffer. Range of total_coef_luma is [0:16].
  [4:0] LUMA5 rw — This register shows total_coef_luma5 of prev data buffer. Writing this register causes the update of total_coef_luma5 field of prev data buffer. Range of total_coef_luma is [0:16].
0x1664 __ALL___CAVLC_NGH_PREV_TCOEF_LUMA1 — CAVLC Previous Data buffer Total Coefficient Data for Luma
  [31:21] Reserved_1 ro — Fixed to 0. Writing this field is ignored. Reading this field returns always 0.
  [20:16] LUMA14 rw — This register shows total_coef_luma14 of prev data buffer. Writing this register causes the update of total_coef_luma14 field of prev data buffer. Range of total_coef_luma is [0:16].
  [15:13] Reserved_2 ro — Fixed to 0. Writing this field is ignored. Reading this field returns always 0.
  [12:8] LUMA11 rw — This register shows total_coef_luma11 of prev data buffer. Writing this register causes the update of total_coef_luma11 field of prev data buffer. Range of total_coef_luma is [0:16].
  [7:5] Reserved_3 ro — Fixed to 0. Writing this field is ignored. Reading this field returns always 0.
  [4:0] LUMA10 rw — This register shows total_coef_luma10 of prev data buffer. Writing this register causes the update of total_coef_luma10 field of prev data buffer. Range of total_coef_luma is [0:16].
0x1668 __ALL___CAVLC_NGH_PREV_TCOEF_CB0 — CAVLC Previous Data buffer Total Coefficient Data for CB
  [39-8n:37-8n] Reserved_{n} ro (n=1..4) — Fixed to 0. Writing this field is ignored. Reading this field returns always 0.
  [28:24] CB7 rw — This register shows total_coef_cb7 of prev data buffer. Writing this register causes the update of total_coef_cb7 field of prev data buffer. Range of total_coef_chroma is [0:16]. Only valid for 4:2:2 mode.
  [20:16] CB5 rw — This register shows total_coef_cb5 of prev data buffer. Writing this register causes the update of total_coef_cb5 field of prev data buffer. Range of total_coef_chroma is [0:16]. Only valid for 4:2:2 mode.
  [12:8] CB3 rw — This register shows total_coef_cb3 of prev data buffer. Writing this register causes the update of total_coef_cb3 field of prev data buffer. Range of total_coef_chroma is [0:16].
  [4:0] CB1 rw — This register shows total_coef_cb1 of prev data buffer. Writing this register causes the update of total_coef_cb1 field of prev data buffer. Range of total_coef_chroma is [0:16].
0x166C __ALL___CAVLC_NGH_PREV_TCOEF_CB1 — CAVLC Previous Data buffer Total Coefficient Data for CB
  [31:13] Reserved_1 ro — Fixed to 0. Writing this field is ignored. Reading this field returns always 0.
  [12:8] CB6 rw — This register shows total_coef_cb11 of prev data buffer. Writing this register causes the update of total_coef_cb11 field of prev data buffer. Range of total_coef_cb is [0:16]. Only valid for 4:2:2 mode.
  [7:5] Reserved_2 ro — Fixed to 0. Writing this field is ignored. Reading this field returns always 0.
  [4:0] CB2 rw — This register shows total_coef_cb2 of prev data buffer. Writing this register causes the update of total_coef_cb2 field of prev data buffer. Range of total_coef_cb is [0:16]. Only valid for 4:2:0 mode
0x1670 __ALL___CAVLC_NGH_PREV_TCOEF_CR0 — CAVLC Previous Data buffer Total Coefficient Data for CR
  [39-8n:37-8n] Reserved_{n} ro (n=1..4) — Fixed to 0. Writing this field is ignored. Reading this field returns always 0.
  [28:24] CR7 rw — This register shows total_coef_cr7 of prev data buffer. Writing this register causes the update of total_coef_cr7 field of prev data buffer. Range of total_coef_chroma is [0:16]. Only valid for 4:2:2 mode.
  [20:16] CR5 rw — This register shows total_coef_cr5 of prev data buffer. Writing this register causes the update of total_coef_cr5 field of prev data buffer. Range of total_coef_chroma is [0:16]. Only valid for 4:2:2 mode.
  [12:8] CR3 rw — This register shows total_coef_cr3 of prev data buffer. Writing this register causes the update of total_coef_cr3 field of prev data buffer. Range of total_coef_chroma is [0:16].
  [4:0] CR1 rw — This register shows total_coef_cr1 of prev data buffer. Writing this register causes the update of total_coef_cr1 field of prev data buffer. Range of total_coef_chroma is [0:16].
0x1674 __ALL___CAVLC_NGH_PREV_TCOEF_CR1 — CAVLC Previous Data buffer Total Coefficient Data for CR
  [31:13] Reserved_1 ro — Fixed to 0. Writing this field is ignored. Reading this field returns always 0.
  [12:8] CR6 rw — This register shows total_coef_cr11 of prev data buffer. Writing this register causes the update of total_coef_cr11 field of prev data buffer. Range of total_coef_cr is [0:16]. Only valid for 4:2:2 mode.
  [7:5] Reserved_2 ro — Fixed to 0. Writing this field is ignored. Reading this field returns always 0.
  [4:0] CR2 rw — This register shows total_coef_cr10 of prev data buffer. Writing this register causes the update of total_coef_cr10 field of prev data buffer. Range of total_coef_cr is [0:16]. Only valid for 4:2:0 mode.
0x1678 __ALL___CAVLC_NGH_PREV_FLAGS — CAVLC Previous Data buffer Flags
  [31] MB_FIELD_DECODING_FLAG rw — This register shows mb_field_decoding_flag of prev data buffer. Writing this register causes the update of mb_field_decoding_flag field of prev data buffer.
  [30:6] Reserved_1 ro — Fixed to 0. Writing this field is ignored. Reading this field returns always 0.
  [5:0] CODED_BLOCK_PATTERN rw — This register shows coded_block_pattern of prev data buffer. Writing this register causes the update of coded_block_pattern field of prev data buffer.
0x167C __ALL___CAVLC_SKIP_RUN_CNT rw — CAVLC Skip Run Count
  [31:28] Reserved_1 — Fixed to 0. Writing this field is ignored. Reading this field returns always 0.
  [27:0] SKIP_RUN_CNT — Skip run counter. Writing this field is ignored during MB processing. After MB processing, this field shows the updated value of skip_run_cnt. Writing this field can be possible between MB processes. The written value is reflected at the beginning of MB processing.
0x1680 __ALL___CAVLC_SKIP_RUN_CNT_SHADOW rw — CAVLC Skip Run Count Shadow
  [31:28] Reserved_1 — Fixed to 0. Writing this field is ignored. Reading this field returns always 0.
  [27:0] SKIP_RUN_CNT — Skip run counter shadow register This register is copied with the value of CAVLC_SKIP_RUN_CNT.SKIP_RUN_CNT at the beginning of MB execution in CAVLC. Thus, when this register is read at the end of an MB execution ( MB N ), it contains that value of the skip run count that was valid at the end of the previous MB execution ( MB N-1 ). This register is to be used by S/W in H.241.
0x16C0 __ALL___DBG_CAP ro reset 0xE00200 — Debug Capability register. Used by debug software to determine which optional debug modules are present and how many instances of each module exist.
  [26] DBG_SWBP_SUP — Specifies whether HWA Core supports SWBP or not. 0 - Not Supported 1 - Supported
  [25] DBQ_RESET_SUP — Specifies whether HWA Core reset is supported or not which does not affect debug logic. 0 - Not Supported 1 - Supported
  [24] SYS_EXE_REQ — Whether HWA Core Execution status and control is supported. 0 - Not Supported 1 - Supported
  [23] TRIG_OUTPUT — 0 -Trigger Outputs are not supported 1 - Trigger Outputs are supported
  [22] TRIG_INPUT — 0 - Trigger Inputs are not supported 1 - Trigger Inputs are supported
  [21:20] TRIG_CHNS — Number of Trigger Channels Supported 0x0 - No channels supported 0x1- One channel supported 0x2 - Two channels supported Others - Reserved
  [19:16] NUM_CNTS — The number of counter modules that exist. The registers supporting the counter modules must be implemented consecutively in the memory map
  [15:12] NUM_WPS — The number of watchpoint modules that exist. The registers supporting the watchpoint modules must be implemented consecutively in the memory map
  [11:8] NUM_BPS — The number of breakpoint modules that exist. The registers supporting the breakpoint modules must be implemented consecutively in the memory map
0x16C4 __ALL___DBG_CTL — Debug Control register. Used by debug software to control all of the basic debug functions
  [19:16] DBG_EMU0_CNTL ro — EMU0 output control. The cross trigger output control. This values in this field determine the behavior of the outputs generated on EMU0. NOTE: The effect of setting 1 is ignored if the HWA Core is currently in HALTED state until the HWA core exits and re-enters HALTED state. 0 : No output. Input only 1 : Pulse on halt. If this bit is set when halted then no effect until the HWA re-enters halted state. 2 : Pulse when any HWBP triggers 3 : Pulse when any HWWP triggers 4 : Drive pin high 5 : Drive pin low 6-15 : Reserved
  [15] Reserved_3 ro — Status of EMU1 input. This bit indicates the current value of the EMU1 input
  [14] DBG_STAT_EMU0 ro — Status of EMU0 input. This bit indicates the current value of the EMU0 input
  [12] DBG_HALT_EMU0 ro — Execution halted due to trigger in on EMU0 input - Set to 1 when halt due to EMU0 input completes - Set to 0 when execution resumes
  [11] DBG_HALT_USER ro — Execution halted due to register update of DBG_HALT - Set to 1 when halt due to DBG_HALT update completes - Set to 0 when execution resumes
  [10] DBG_HALT_STEP ro — Execution halted due to single step completion - Set to 1 when the single step completes - Set to 0 when execution resumes
  [9] DBG_HALT_BPWP ro — Execution halted due to trigger from HWBP or WP. - Set to ‘1’ halt due to breakpoint or watchpoint completes - Set to ‘0’ when execution resumes
  [7] DBG_EXE_STAT ro — The execution status of the module - Set to ‘1’ when halted due to debug event - Set to ‘0’ when execution resumes
  [6] DBG_EMU1_EN rw — EMU1 input trigger enable - Writing ‘1’ enables halting on the falling edge of the EMU1 input - Writing ‘0’ disables halts via EMU1 input
  [5] DBG_EMU0_EN rw — EMU0 input trigger enable - Writing ‘1’ enables halting on the falling edge of the EMU1 input - Writing ‘0’ disables halts via EMU0 input
  [4] DBG_WPBP_EN rw — This bit enables the halts on watchpoint or hardware breakpoint trigger events. - Writing ‘1’ enables halting on any hardware breakpoint or watchpoint trigger - Each breakpoint or watchpoint resource also has a local enable - Writing ‘0’ disables halts via hardware breakpoints or watchpoints
  [2] DBG_SINGLE_STEP_EN rw — Single Step Execution enable. When this bit is set, the accelerator core shall be halted upon execution of a single instruction. This is after the accelerator core has left the halted state by clearing the DBG_HALT control bit. - Writing ‘1’ enables halting when the next instruction following exit from halted state is executed. - Writing ‘0’ disables halts via single step. NOTE: 1. When the accelerator core enters its natural execution state, it may or may not execute an instruction and re-enter HALTED state.
  [1] DBG_RESTART rw — Debug Restart Status bit. This bit is normally set when the DBG_HALT bit transitions from ‘1’ to ‘0’ when the natural execution state is entered. It is a sticky bit. It may also be set when a synchronous run causes the accelerator to leave halted state. - Reading ‘1’ means HWA Core exited halted state (at least temporarily). - Reading ‘0’ means HWA Core did not exit halted state. - Writing ‘1’ shall clear the bit if set. There is no restriction on when it can be cleared. - Writing ‘0’ shall have no effect.
  [0] DBG_HALT rw — 0 DBG_HALT Global debug run control. The bit will be read as being set upon entry to HALTED state due to halted state being entered because of SWBP, HWBP, HWWP, EMU0 / 1 trigger or manual halt requested through this control. - Writing ‘1’ when read ‘0’ shall cause a halt on the next possible halt boundary. - Writing ‘0’ when read ‘1’ returns the system to the natural execution state. A synchronous run hardware request has the same effect. - Reading ‘1’ means that the halted state has been reached or been requested by the manual halt mechanism - Reading ‘0’ means that the target is in its natural execution state. NOTE: 1. The natural execution state means the FSM state entered prior to last entry into Halted state. 2. This would be the last application requested FSM state unless the DBG_SYS_EXE_REQ control was used to change it.
0x1700 __ALL___DBG_HWBP_0_CTL — Hardware Breakpoint Control for FE
  [2] TRIGGERED rw — This bit is Set to "1" when HWBP located at the MB_Index in DBG_HWBP_n_MB_Index is executed Set to ‘1’ when executing the MB index = DBG_HWBP_n_MB_Index Cleared to ‘0’ by writing ‘1’ to this bit
  [1] HALT rw — This bit configures the module to generate halt when triggered Writing ‘1’ enables a HWA halt when triggered. The DBG_CNTL:DBG_HALT_BPWP must also be set for the halt to occur Writing ‘0’ disables halt upon trigger
  [0] ENABLE rw — This is the local enable for the hardware breakpoint module Writing ‘1’ to this bit enables the module to generate an instruction address match trigger Writing ‘0’ to this bit disables the module
0x1704 __ALL___DBG_HWBP_0_MB_INDEX — Hardware Breakpoint MB-Index for FE
  [24:16] COLUMN_INDEX rw — Column index for breakpoint
  [8:0] ROW_INDEX rw — Row index for breakpoint
0x170C __ALL___DBG_HWBP_0_AMASK — Hardware Breakpoint Mask for MB-Index for FE
  fields as __ALL___DBG_HWBP_0_MB_INDEX
0x1740 __ALL___DBG_HWBP_1_CTL — Hardware Breakpoint Control for BE
  fields as __ALL___DBG_HWBP_0_CTL
0x1744 __ALL___DBG_HWBP_1_MB_INDEX — Hardware Breakpoint MB-Index for BE
  fields as __ALL___DBG_HWBP_0_MB_INDEX
0x174C __ALL___DBG_HWBP_1_AMASK — Hardware Breakpoint mask for MB-Index for BE
  fields as __ALL___DBG_HWBP_0_MB_INDEX
0x1780 __ALL___SCHEDULER_STATUS ro — HTS status
  [2] PIPEDOWN — HWA is in pipedown
  [1] EXE — HWA is executing
  [0] INIT — HWA is autoloading/initializing
0x1790 __ALL___HWA_THREAD_STATUS ro — HTS status
  [6] HALT_DEBUG_OUT — Halted because of debug out request
  [5] HALT_DEBUG_IN — Halted because of pi_emu
  [4] HALT_REWIND — Halted because of rewind
  [3] HALT_PIPEDOWN — Thread piped down
  [2] HALT_INTR — Halted because of interrupt request
  [1] EXE — Execution state
  [0] WAIT — Waiting for the Tstart_req
0x1800 __ALL___CFG_RSVD0_START ro — Reserved Config Address Start
0x1FFC __ALL___CFG_RSVD0_END ro — Reserved Config Address End
0x3FFC __ALL___CFG_RSVD1_START ro — Reserved Config Address End
0x4000 __ALL___MEM_START rw — ECD5 Memory Address Start
  [31:0] MEM
0x77FC __ALL___MEM_END rw — ECD5 Memory Address End
  [31:0] MEM
0x7800 __ALL___MEM_RSVD0_START ro — Reserved Mem Address Start
0x7FFC __ALL___MEM_RSVD0_END ro — Reserved Mem Address end
0x8000 __ALL___MEM_RSVD1_START ro — Reserved Mem Address Start
0xBFFC __ALL___MEM_RSVD1_END ro — Reserved Mem Address end
